# STM32L5x2 register map
File version: 1.3
Registers are 32-bit, read-write, reset 0x0 unless marked. A register's access mark holds for its fields unless they carry their own. Offsets are from the block's base; [hi:lo] are bit positions; {n}, {i} and the like mark numbered series; 'fields as' and 'values as' point back to an identical list.

## DMAMUX1 — Direct memory access Multiplexer
Base 0x40020800
Same registers: SEC_DMAMUX1 0x50020800
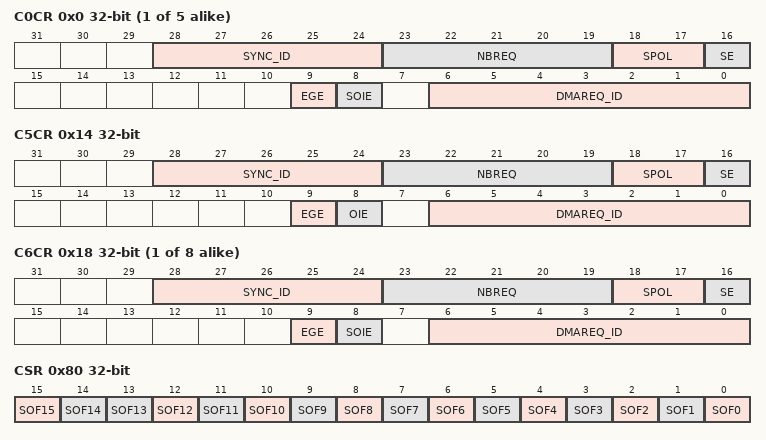
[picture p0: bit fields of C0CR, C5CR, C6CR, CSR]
{0x0+4i} C{i}CR (i=0..4) — DMA Multiplexer Channel {i} Control register
  [28:24] SYNC_ID
  [23:19] NBREQ — Nb request
  [18:17] SPOL — Sync polarity
  [16] SE — Synchronization enable
  [9] EGE — Event Generation Enable
  [8] SOIE — Synchronization Overrun Interrupt Enable
  [6:0] DMAREQ_ID — DMA Request ID
0x14 C5CR — DMA Multiplexer Channel 5 Control register
  [28:24] SYNC_ID
  [23:19] NBREQ — Nb request
  [18:17] SPOL — Sync polarity
  [16] SE — Synchronization enable
  [9] EGE — Event Generation Enable
  [8] OIE — Synchronization Overrun Interrupt Enable
  [6:0] DMAREQ_ID — DMA Request ID
{0x0+4i} C{i}CR (i=6..13) — DMA Multiplexer Channel {i} Control register
  fields as C0CR
0x80 CSR — DMA Multiplexer Channel Status register
  [15] SOF15 — Synchronization Overrun Flag 13
  [14] SOF14 — Synchronization Overrun Flag 13
  [n] SOF{n} (n=0..13) — Synchronization Overrun Flag {n}
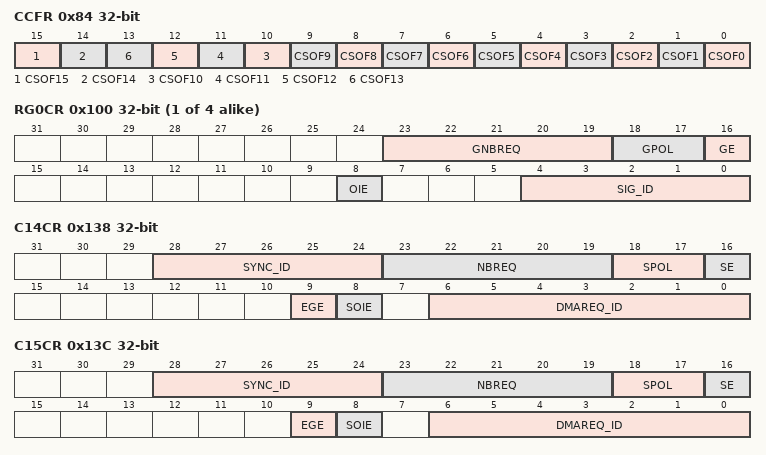
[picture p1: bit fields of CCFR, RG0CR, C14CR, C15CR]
0x84 CCFR — DMA Channel Clear Flag Register
  [15] CSOF15 — Synchronization Clear Overrun Flag 13
  [14] CSOF14 — Synchronization Clear Overrun Flag 13
  [n] CSOF{n} (n=0..13) — Synchronization Clear Overrun Flag {n}
{0x100+4i} RG{i}CR (i=0..3) — DMA Request Generator {i} Control Register
  [23:19] GNBREQ — Number of Request
  [18:17] GPOL — Generation Polarity
  [16] GE — Generation Enable
  [8] OIE — Overrun Interrupt Enable
  [4:0] SIG_ID — Signal ID
0x138 C14CR — DMA Multiplexer Channel 10 Control register
  [28:24] SYNC_ID — Synchronization identification
  [23:19] NBREQ — Number of DMA requests minus 1 to forward
  [18:17] SPOL — Synchronization polarity
  [16] SE — Synchronization enable
  [9] EGE — Event generation enable
  [8] SOIE — Synchronization overrun interrupt enable
  [6:0] DMAREQ_ID — DMA request identification
0x13C C15CR — DMA Multiplexer Channel 10 Control register
  fields as C14CR
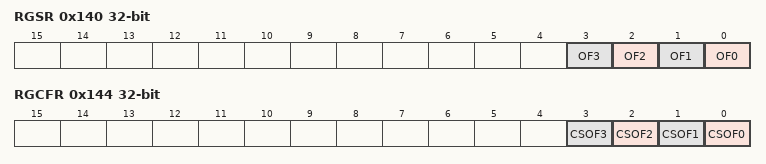
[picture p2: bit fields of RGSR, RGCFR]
0x140 RGSR ro — DMA Request Generator Status Register
  [n] OF{n} (n=0..3) — Generator Overrun Flag {n}
0x144 RGCFR — DMA Request Generator Clear Flag Register
  [n] CSOF{n} (n=0..3) — Generator Clear Overrun Flag {n}

## EXTI — External interrupt/event controller
Base 0x4002F400
Same registers: SEC_EXTI 0x5002F400
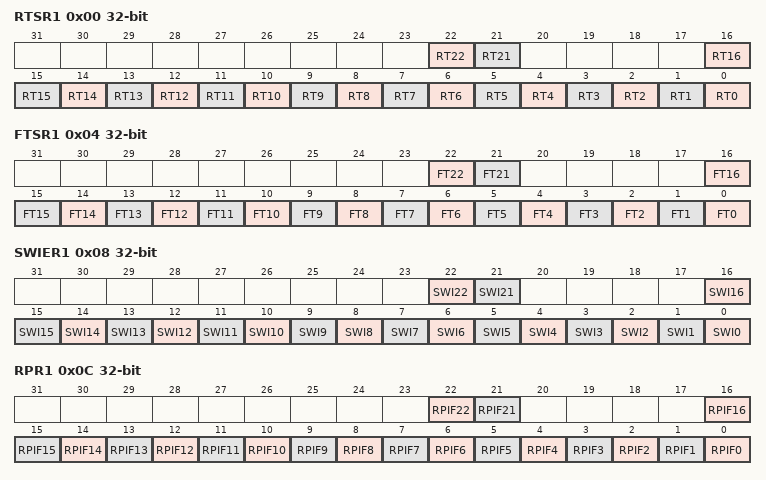
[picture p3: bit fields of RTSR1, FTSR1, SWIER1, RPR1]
0x00 RTSR1 — EXTI rising trigger selection register
  [22] RT22 — Rising trigger event configuration bit of configurable event input x
  [21] RT21 — Rising trigger event configuration bit of configurable event input x
  [n] RT{n} (n=0..16) — Rising trigger event configuration bit of configurable event input x
0x04 FTSR1 — EXTI falling trigger selection register
  [22] FT22 — Falling trigger event configuration bit of configurable event input x
  [21] FT21 — Falling trigger event configuration bit of configurable event input x
  [n] FT{n} (n=0..16) — Falling trigger event configuration bit of configurable event input x
0x08 SWIER1 — EXTI software interrupt event register
  [22] SWI22 — Software interrupt on event x
  [21] SWI21 — Software interrupt on event x
  [n] SWI{n} (n=0..16) — Software interrupt on event x
0x0C RPR1 — EXTI rising edge pending register
  [22] RPIF22 — configurable event inputs x rising edge pending bit
  [21] RPIF21 — configurable event inputs x rising edge pending bit
  [n] RPIF{n} (n=0..16) — configurable event inputs x rising edge pending bit
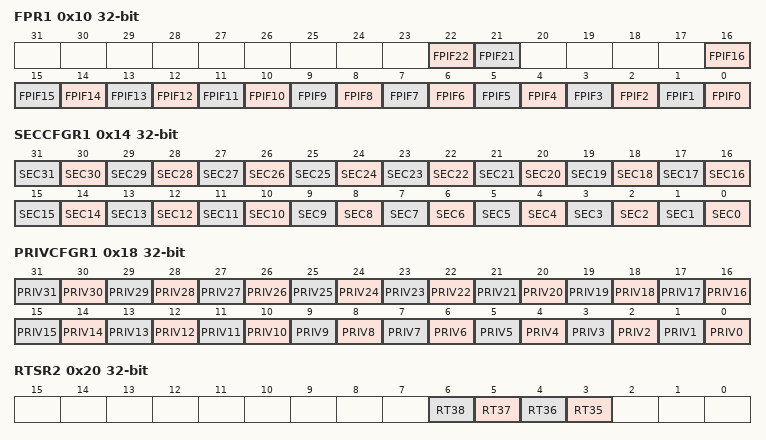
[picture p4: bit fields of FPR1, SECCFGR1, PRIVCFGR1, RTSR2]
0x10 FPR1 — EXTI falling edge pending register
  [22] FPIF22 — configurable event inputs x falling edge pending bit.
  [21] FPIF21 — configurable event inputs x falling edge pending bit.
  [n] FPIF{n} (n=0..16) — configurable event inputs x falling edge pending bit.
0x14 SECCFGR1 — EXTI security configuration register
  [n] SEC{n} (n=0..31) — Security enable on event input x
0x18 PRIVCFGR1 — EXTI privilege configuration register
  [n] PRIV{n} (n=0..31) — Security enable on event input x
0x20 RTSR2 — EXTI rising trigger selection register
  [n-32] RT{n} (n=35..38) — Rising trigger event configuration bit of configurable event input x
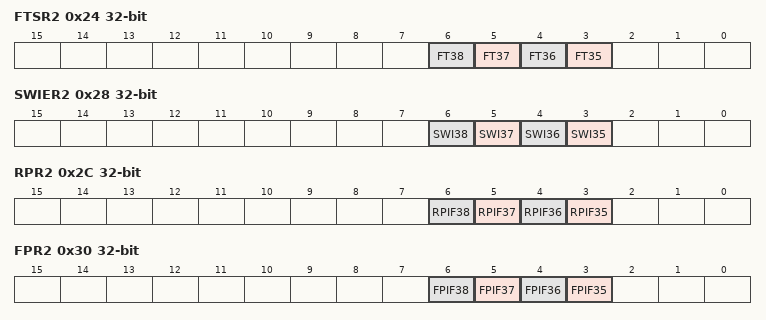
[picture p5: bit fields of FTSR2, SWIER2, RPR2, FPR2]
0x24 FTSR2 — EXTI falling trigger selection register
  [n-32] FT{n} (n=35..38)
0x28 SWIER2 — EXTI software interrupt event register
  [n-32] SWI{n} (n=35..38)
0x2C RPR2 — EXTI rising edge pending register
  [n-32] RPIF{n} (n=35..38)
0x30 FPR2 — EXTI falling edge pending register
  [n-32] FPIF{n} (n=35..38)
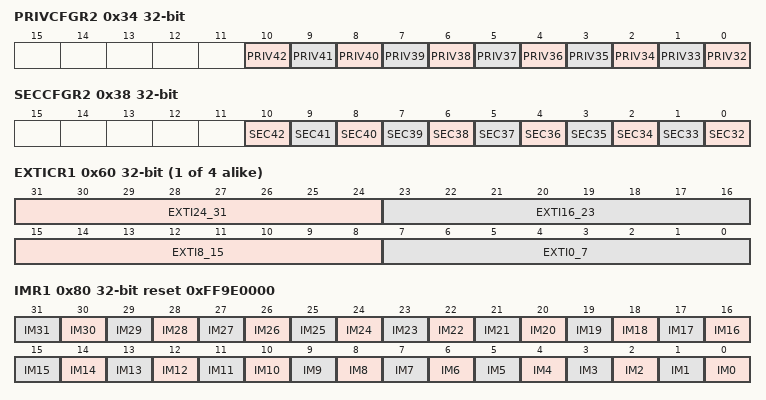
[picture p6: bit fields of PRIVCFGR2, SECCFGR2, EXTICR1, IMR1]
0x34 PRIVCFGR2 — EXTI security enable register
  [n-32] PRIV{n} (n=32..42)
0x38 SECCFGR2 — EXTI security enable register
  [n-32] SEC{n} (n=32..42)
{0x5C+4i} EXTICR{i} (i=1..4) — EXTI external interrupt selection register
  [31:24] EXTI24_31 — EXTIm+3 GPIO port selection
  [23:16] EXTI16_23 — EXTIm+2 GPIO port selection
  [15:8] EXTI8_15 — EXTIm+1 GPIO port selection
  [7:0] EXTI0_7 — EXTIm GPIO port selection
0x70 LOCKRG — EXTI lock register
  [0] LOCK
0x80 IMR1 reset 0xFF9E0000 — EXTI CPU wakeup with interrupt mask register
  [n] IM{n} (n=0..31) — CPU wakeup with interrupt mask on event input
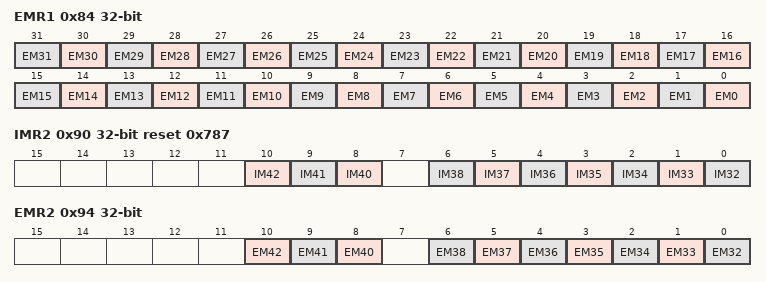
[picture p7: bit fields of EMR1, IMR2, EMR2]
0x84 EMR1 — EXTI CPU wakeup with event mask register
  [n] EM{n} (n=0..31) — CPU wakeup with interrupt mask on event input
0x90 IMR2 reset 0x787 — EXTI CPUm wakeup with interrupt mask register
  [10] IM42 — CPU wakeup with interrupt mask on event input
  [9] IM41 — CPU wakeup with interrupt mask on event input
  [8] IM40 — CPU wakeup with interrupt mask on event input
  [n-32] IM{n} (n=32..38) — CPU wakeup with interrupt mask on event input
0x94 EMR2 — EXTI CPU wakeup with event mask register
  [10] EM42 — CPU wakeup with interrupt mask on event input
  [9] EM41 — CPU wakeup with interrupt mask on event input
  [8] EM40 — CPU wakeup with interrupt mask on event input
  [n-32] EM{n} (n=32..38) — CPU wakeup with interrupt mask on event input
